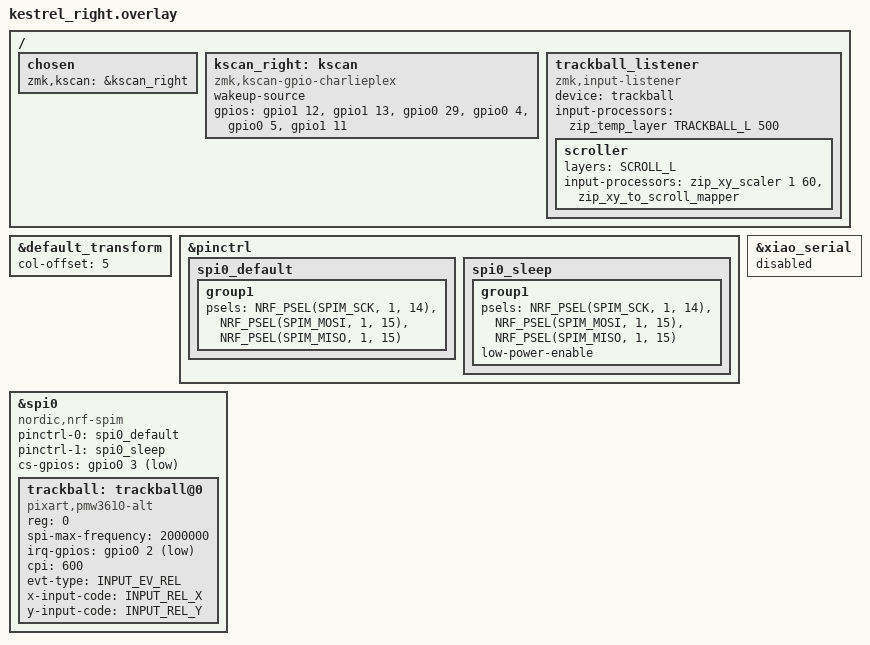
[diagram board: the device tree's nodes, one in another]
#include "kestrel.dtsi"
#include <dt-bindings/input/input-event-codes.h>
#include <zephyr/dt-bindings/input/input-event-codes.h>

&default_transform {
    col-offset = <5>;
};

/ {
    chosen {
        zmk,kscan = &kscan_right;
    };

kscan_right: kscan {
    compatible = "zmk,kscan-gpio-charlieplex";
    wakeup-source;

    gpios = <&gpio1 12  GPIO_ACTIVE_HIGH>,
             <&gpio1 13 GPIO_ACTIVE_HIGH>,
             <&gpio0 29 GPIO_ACTIVE_HIGH>,
             <&gpio0 4 GPIO_ACTIVE_HIGH>,
             <&gpio0 5 GPIO_ACTIVE_HIGH>,
             <&gpio1 11 GPIO_ACTIVE_HIGH>;

    //interrupt-gpios = <&gpio0 28 (GPIO_ACTIVE_HIGH | GPIO_PULL_DOWN)>;
    };
};

&pinctrl {
    spi0_default: spi0_default {
        group1 {
            psels = <NRF_PSEL(SPIM_SCK, 1, 14)>,
            <NRF_PSEL(SPIM_MOSI, 1, 15)>,
            <NRF_PSEL(SPIM_MISO, 1, 15)>;
        };
    };

    spi0_sleep: spi0_sleep {
        group1 {
            psels = <NRF_PSEL(SPIM_SCK, 1, 14)>,
                    <NRF_PSEL(SPIM_MOSI, 1, 15)>,
                    <NRF_PSEL(SPIM_MISO, 1, 15)>;
            low-power-enable;
        };
    };
};

&spi0 {
    compatible = "nordic,nrf-spim";
    status = "okay";
    pinctrl-0 = <&spi0_default>;
    pinctrl-1 = <&spi0_sleep>;
    pinctrl-names = "default", "sleep";
    cs-gpios = <&gpio0 3 GPIO_ACTIVE_LOW>;

    trackball: trackball@0 {
        status = "okay";
        compatible = "pixart,pmw3610-alt";
        reg = <0>;
        spi-max-frequency = <2000000>;
        irq-gpios = <&gpio0 2 (GPIO_ACTIVE_LOW | GPIO_PULL_UP)>;
        cpi = <600>;
        evt-type = <INPUT_EV_REL>;
        x-input-code = <INPUT_REL_X>;
        y-input-code = <INPUT_REL_Y>;
        // disable force-awake
        // force-awake;
    };
};

/ {
  trackball_listener {
    compatible = "zmk,input-listener";
    device = <&trackball>;
    input-processors = <&zip_temp_layer TRACKBALL_L 500>;

   scroller {
    layers = <SCROLL_L>;
    input-processors = <&zip_xy_scaler 1 60 &zip_xy_to_scroll_mapper>;
        };
    };
};

&xiao_serial {
    status = "disabled";
};
